# MK50D10 register map
Vendor: Freescale Semiconductor, Inc.; Series: Kinetis_K; File version: 1.6
CPU: CM4 r0p1, little endian, no MPU, no FPU, VTOR, 4 interrupt priority bits
Registers are 8-bit, read-write, reset 0x0 unless marked. A register's access mark holds for its fields unless they carry their own. Offsets are from the block's base; [hi:lo] are bit positions; {n}, {i} and the like mark numbered series; 'fields as' and 'values as' point back to an identical list.

## AIPS0 — AIPS-Lite Bridge
Base 0x40000000; register names take the prefix AIPS0_
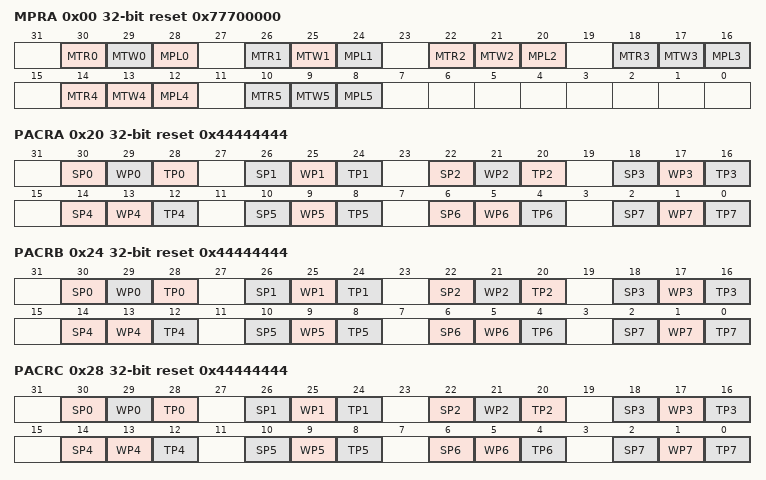
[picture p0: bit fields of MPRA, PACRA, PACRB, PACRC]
0x00 MPRA 32-bit reset 0x77700000 — Master Privilege Register A
  [30] MTR0 — Master Trusted For Read
    0=This master is not trusted for read accesses; 1=This master is trusted for read accesses
  [29] MTW0 — Master Trusted For Writes
    0=This master is not trusted for write accesses; 1=This master is trusted for write accesses
  [28] MPL0 — Master Privilege Level
    0=Accesses from this master are forced to user-mode; 1=Accesses from this master are not forced to user-mode
  [26] MTR1 — Master trusted for read
    values as MTR0
  [25] MTW1 — Master trusted for writes
    values as MTW0
  [24] MPL1 — Master privilege level
    values as MPL0
  [30-4n] MTR{n} (n=2..5) — Master Trusted For Read
    values as MTR0
  [29-4n] MTW{n} (n=2..5) — Master Trusted For Writes
    values as MTW0
  [28-4n] MPL{n} (n=2..5) — Master Privilege Level
    values as MPL0
0x20 PACRA 32-bit reset 0x44444444 — Peripheral Access Control Register
  [30] SP0 — Supervisor Protect
    0=This peripheral does not require supervisor privilege level for accesses; 1=This peripheral requires supervisor privilege level for accesses
  [29] WP0 — Write protect
    0=This peripheral allows write accesses; 1=This peripheral is write protected
  [28] TP0 — Trusted Protect
    0=Accesses from an untrusted master are allowed; 1=Accesses from an untrusted master are not allowed
  [26] SP1 — Supervisor Protect
    values as SP0
  [25] WP1 — Write Protect
    values as WP0
  [24] TP1 — Trusted protect
    values as TP0
  [22] SP2 — Supervisor Protect
    values as SP0
  [21] WP2 — Write protect
    values as WP0
  [20] TP2 — Trusted Protect
    values as TP0
  [18] SP3 — Supervisor protect
    values as SP0
  [17] WP3 — Write Protect
    values as WP0
  [16] TP3 — Trusted protect
    values as TP0
  [30-4n] SP{n} (n=4..7) — Supervisor Protect
    values as SP0
  [13] WP4 — Write protect
    values as WP0
  [12] TP4 — Trusted protect
    values as TP0
  [9] WP5 — Write Protect
    values as WP0
  [8] TP5 — Trusted Protect
    values as TP0
  [5] WP6 — Write Protect
    values as WP0
  [4] TP6 — Trusted Protect
    values as TP0
  [1] WP7 — Write Protect
    values as WP0
  [0] TP7 — Trusted Protect
    values as TP0
0x24 PACRB 32-bit reset 0x44444444 — Peripheral Access Control Register
  fields as PACRA
0x28 PACRC 32-bit reset 0x44444444 — Peripheral Access Control Register
  fields as PACRA
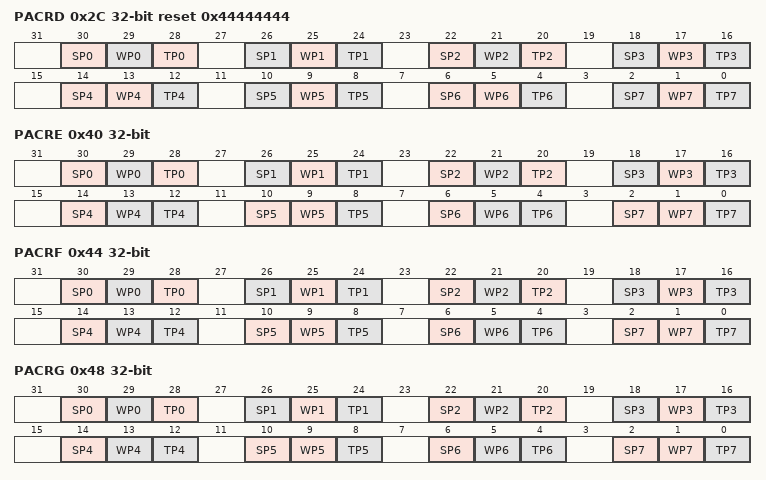
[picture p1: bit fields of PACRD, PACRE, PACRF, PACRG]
0x2C PACRD 32-bit reset 0x44444444 — Peripheral Access Control Register
  fields as PACRA
0x40 PACRE 32-bit reset not defined — Peripheral Access Control Register
  [30] SP0 — Supervisor Protect
    values as PACRA.SP0
  [29] WP0 — Write Protect
    values as PACRA.WP0
  [28] TP0 — Trusted protect
    values as PACRA.TP0
  [26] SP1 — Supervisor Protect
    values as PACRA.SP0
  [25] WP1 — Write Protect
    values as PACRA.WP0
  [24] TP1 — Trusted Protect
    values as PACRA.TP0
  [22] SP2 — Supervisor protect
    values as PACRA.SP0
  [21] WP2 — Write Protect
    values as PACRA.WP0
  [20] TP2 — Trusted protect
    values as PACRA.TP0
  [18] SP3 — Supervisor Protect
    values as PACRA.SP0
  [17] WP3 — Write protect
    values as PACRA.WP0
  [16] TP3 — Trusted Protect
    values as PACRA.TP0
  [14] SP4 — Supervisor protect
    values as PACRA.SP0
  [29-4n] WP{n} (n=4..7) — Write Protect
    values as PACRA.WP0
  [12] TP4 — Trusted protect
    values as PACRA.TP0
  [10] SP5 — Supervisor Protect
    values as PACRA.SP0
  [8] TP5 — Trusted Protect
    values as PACRA.TP0
  [6] SP6 — Supervisor Protect
    values as PACRA.SP0
  [4] TP6 — Trusted Protect
    values as PACRA.TP0
  [2] SP7 — Supervisor Protect
    values as PACRA.SP0
  [0] TP7 — Trusted Protect
    values as PACRA.TP0
0x44 PACRF 32-bit reset not defined — Peripheral Access Control Register
  fields as PACRE
0x48 PACRG 32-bit reset not defined — Peripheral Access Control Register
  fields as PACRE
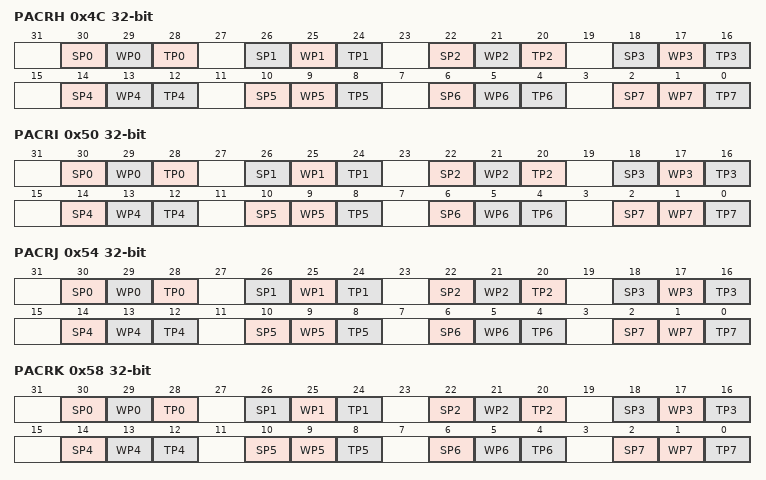
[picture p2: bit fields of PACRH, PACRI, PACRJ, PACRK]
0x4C PACRH 32-bit reset not defined — Peripheral Access Control Register
  fields as PACRE
0x50 PACRI 32-bit reset not defined — Peripheral Access Control Register
  fields as PACRE
0x54 PACRJ 32-bit reset not defined — Peripheral Access Control Register
  fields as PACRE
0x58 PACRK 32-bit reset not defined — Peripheral Access Control Register
  fields as PACRE
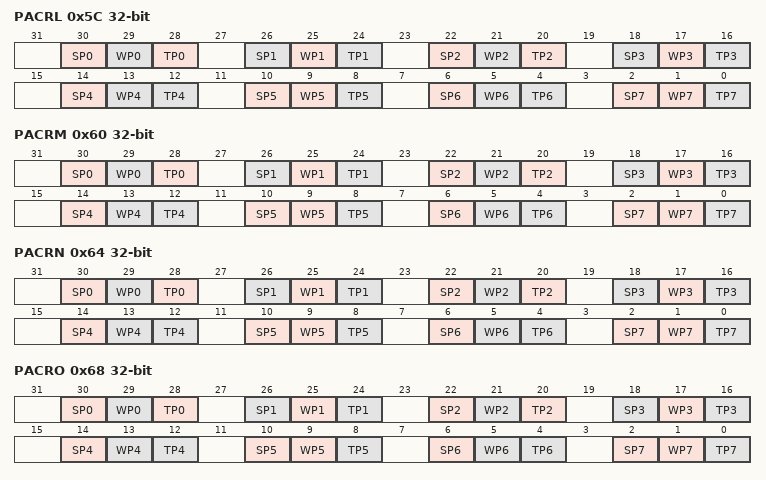
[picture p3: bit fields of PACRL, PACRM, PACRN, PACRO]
0x5C PACRL 32-bit reset not defined — Peripheral Access Control Register
  fields as PACRE
0x60 PACRM 32-bit reset not defined — Peripheral Access Control Register
  fields as PACRE
0x64 PACRN 32-bit reset not defined — Peripheral Access Control Register
  fields as PACRE
0x68 PACRO 32-bit reset not defined — Peripheral Access Control Register
  fields as PACRE
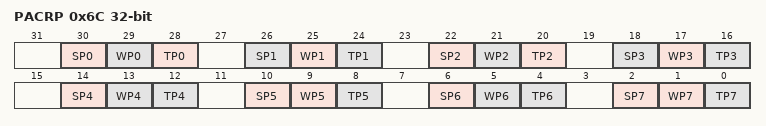
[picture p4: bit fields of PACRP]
0x6C PACRP 32-bit reset not defined — Peripheral Access Control Register
  fields as PACRE

## AIPS1 — AIPS-Lite Bridge
Base 0x40080000; register names take the prefix AIPS1_
Registers as AIPS0.

## Notices in the file
Redistribution and use in source and binary forms, with or without modification,
are permitted provided that the following conditions are met:
o Redistributions of source code must retain the above copyright notice, this list
of conditions and the following disclaimer.
o Redistributions in binary form must reproduce the above copyright notice, this
list of conditions and the following disclaimer in the documentation and/or
other materials provided with the distribution.
o Neither the name of Freescale Semiconductor, Inc. nor the names of its
contributors may be used to endorse or promote products derived from this
software without specific prior written permission.
THIS SOFTWARE IS PROVIDED BY THE COPYRIGHT HOLDERS AND CONTRIBUTORS "AS IS" AND
ANY EXPRESS OR IMPLIED WARRANTIES, INCLUDING, BUT NOT LIMITED TO, THE IMPLIED
WARRANTIES OF MERCHANTABILITY AND FITNESS FOR A PARTICULAR PURPOSE ARE
DISCLAIMED. IN NO EVENT SHALL THE COPYRIGHT HOLDER OR CONTRIBUTORS BE LIABLE FOR
ANY DIRECT, INDIRECT, INCIDENTAL, SPECIAL, EXEMPLARY, OR CONSEQUENTIAL DAMAGES
(INCLUDING, BUT NOT LIMITED TO, PROCUREMENT OF SUBSTITUTE GOODS OR SERVICES;
LOSS OF USE, DATA, OR PROFITS; OR BUSINESS INTERRUPTION) HOWEVER CAUSED AND ON
ANY THEORY OF LIABILITY, WHETHER IN CONTRACT, STRICT LIABILITY, OR TORT
(INCLUDING NEGLIGENCE OR OTHERWISE) ARISING IN ANY WAY OUT OF THE USE OF THIS
SOFTWARE, EVEN IF ADVISED OF THE POSSIBILITY OF SUCH DAMAGE.
